# CH32X315 register map
Vendor: WCH Ltd.; File version: 1.1
Registers are 32-bit, read-write, reset 0x0 unless marked. A register's access mark holds for its fields unless they carry their own. Offsets are from the block's base; [hi:lo] are bit positions.

## RCC — Reset and clock control
Base 0x40021000
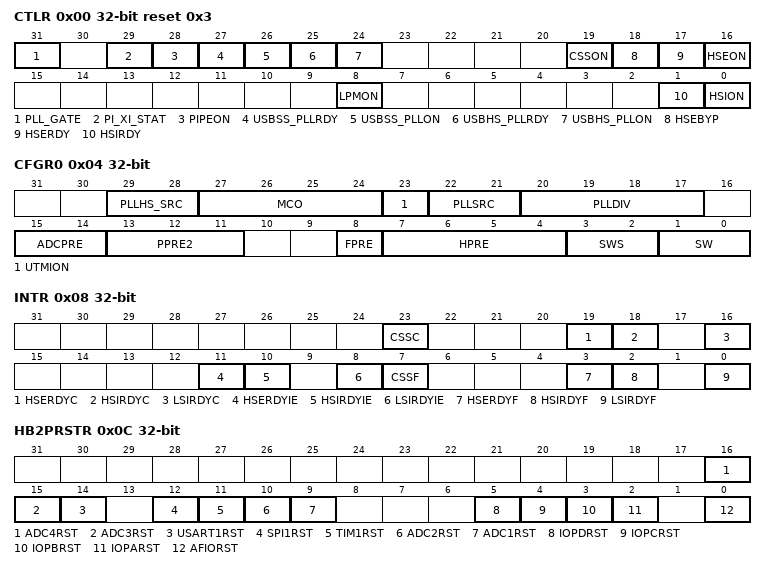
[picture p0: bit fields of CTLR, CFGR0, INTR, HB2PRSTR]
0x00 CTLR access per field reset 0x3 — Clock control register
  [31] PLL_GATE rw — PLL clock gating enablement
  [29] PI_XI_STAT ro — Crystal oscillator indication bit
  [28] PIPEON rw — PIPE clock gating enablement
  [27] USBSS_PLLRDY ro — USBSS PLL clock ready flag
  [26] USBSS_PLLON rw — USBSS PLL clock enable
  [25] USBHS_PLLRDY ro — USBHS PLL clock ready flag
  [24] USBHS_PLLON rw — USBHS PLL clock enable
  [19] CSSON rw — Clock Security System enable
  [18] HSEBYP rw — External High Speed clock Bypass
  [17] HSERDY ro — External High Speed clock ready flag
  [16] HSEON rw — External High Speed clock enable
  [8] LPMON rw — LMP clock enable
  [1] HSIRDY ro — Internal High Speed clock ready flag
  [0] HSION rw — Internal High Speed clock enable
0x04 CFGR0 access per field — Clock configuration register (RCC_CFGR0)
  [29:28] PLLHS_SRC rw — PLL clock selection
  [27:24] MCO rw — Microcontroller clock output
  [23] UTMION rw — UTMI clock gating enable
  [22:21] PLLSRC rw — PLLCLK clock selection
  [20:17] PLLDIV rw — The frequency division ratios of the UBSSS PLL 625M clock and USBHS PLL 480M clock
  [15:14] ADCPRE rw — ADC prescaler
  [13:11] PPRE2 rw — ADC clock prescaler (PB2)
  [8] FPRE rw — HCLK clock pre-divider selection
  [7:4] HPRE rw — HB prescaler
  [3:2] SWS ro — System Clock Switch Status
  [1:0] SW rw — System clock Switch
0x08 INTR access per field — Clock interrupt register (RCC_INTR)
  [23] CSSC wo — Clock security system interrupt clear
  [19] HSERDYC wo — HSE Ready Interrupt Clear
  [18] HSIRDYC wo — HSI Ready Interrupt Clear
  [16] LSIRDYC wo — LSI Ready Interrupt Clear
  [11] HSERDYIE rw — HSE Ready Interrupt Enable
  [10] HSIRDYIE rw — HSI Ready Interrupt Enable
  [8] LSIRDYIE rw — LSI Ready Interrupt Enable
  [7] CSSF ro — Clock Security System Interrupt flag
  [3] HSERDYF ro — HSE Ready Interrupt flag
  [2] HSIRDYF ro — HSI Ready Interrupt flag
  [0] LSIRDYF ro — LSI Ready Interrupt flag
0x0C HB2PRSTR — HB2 peripheral reset register (RCC_HB2PRSTR)
  [16] ADC4RST — ADC4 reset
  [15] ADC3RST — ADC3 reset
  [14] USART1RST — USART1 reset
  [12] SPI1RST — SPI 1 reset
  [11] TIM1RST — TIM1 timer reset
  [10] ADC2RST — ADC 2 interface reset
  [9] ADC1RST — ADC 1 interface reset
  [5] IOPDRST — IO port D reset
  [4] IOPCRST — IO port C reset
  [3] IOPBRST — IO port B reset
  [2] IOPARST — IO port A reset
  [0] AFIORST — Alternate function I/O reset
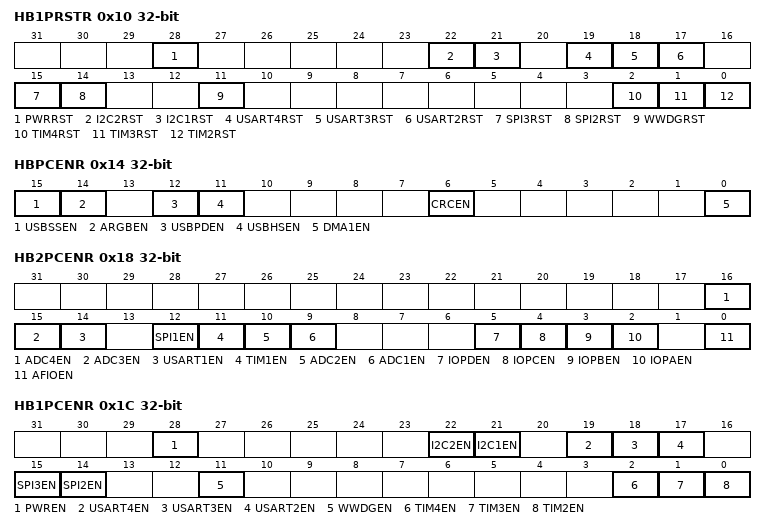
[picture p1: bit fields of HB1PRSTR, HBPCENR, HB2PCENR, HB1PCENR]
0x10 HB1PRSTR — HB1 peripheral reset register (RCC_HB1PRSTR)
  [28] PWRRST — Power interface reset
  [22] I2C2RST — I2C2 reset
  [21] I2C1RST — I2C1 reset
  [19] USART4RST — USART 4 reset
  [18] USART3RST — USART 3 reset
  [17] USART2RST — USART 2 reset
  [15] SPI3RST — SPI3 reset
  [14] SPI2RST — SPI2 reset
  [11] WWDGRST — Window watchdog reset
  [2] TIM4RST — Timer 4 reset
  [1] TIM3RST — Timer 3 reset
  [0] TIM2RST — Timer 2 reset
0x14 HBPCENR — HB Peripheral Clock enable register (RCC_HBPCENR)
  [15] USBSSEN — USBSS clock enable
  [14] ARGBEN — ARGB clock enable
  [12] USBPDEN — USBPD clock enable
  [11] USBHSEN — USBHS clock enable
  [6] CRCEN — CRC clock enable
  [0] DMA1EN — DMA clock enable
0x18 HB2PCENR — HB2 peripheral clock enable register (RCC_HB2PCENR)
  [16] ADC4EN — ADC4 clock enable
  [15] ADC3EN — ADC3 clock enable
  [14] USART1EN — USART1 clock enable
  [12] SPI1EN — SPI 1 clock enable
  [11] TIM1EN — TIM1 Timer clock enable
  [10] ADC2EN — ADC 2 interface clock enable
  [9] ADC1EN — ADC1 interface clock enable
  [5] IOPDEN — I/O port D clock enable
  [4] IOPCEN — I/O port C clock enable
  [3] IOPBEN — I/O port B clock enable
  [2] IOPAEN — I/O port A clock enable
  [0] AFIOEN — Alternate function I/O clock enable
0x1C HB1PCENR — HB1 peripheral clock enable register (RCC_HB1PCENR)
  [28] PWREN — Power interface clock enable
  [22] I2C2EN — I2C2 clock enable
  [21] I2C1EN — I2C1 clock enable
  [19] USART4EN — USART4 clock enable
  [18] USART3EN — USART3 clock enable
  [17] USART2EN — USART2 clock enable
  [15] SPI3EN — SPI3 clock enable
  [14] SPI2EN — SPI2 clock enable
  [11] WWDGEN — Window watchdog clock enable
  [2] TIM4EN — Timer 4 clock enable
  [1] TIM3EN — Timer 3 clock enable
  [0] TIM2EN — Timer 2 clock enable
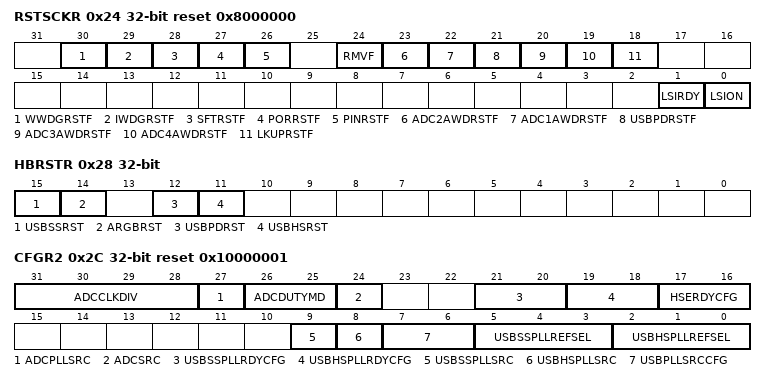
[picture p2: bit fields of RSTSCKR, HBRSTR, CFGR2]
0x24 RSTSCKR access per field reset 0x8000000 — Control/status register (RCC_RSTSCKR)
  [30] WWDGRSTF ro — Window watchdog reset flag
  [29] IWDGRSTF ro — Independent watchdog reset flag
  [28] SFTRSTF ro — Software reset flag
  [27] PORRSTF ro — POR/PDR reset flag
  [26] PINRSTF ro — PIN reset flag
  [24] RMVF rw — Remove reset flag
  [23] ADC2AWDRSTF ro — ADC2 watchdog reset flag
  [22] ADC1AWDRSTF ro — ADC1 watchdog flag
  [21] USBPDRSTF ro — USBPD reset flag
  [20] ADC3AWDRSTF ro — ADC3 watchdog reset flag
  [19] ADC4AWDRSTF ro — ADC4 watchdog flag
  [18] LKUPRSTF ro — LOCKUP reset flag
  [1] LSIRDY ro — Internal low speed oscillator ready
  [0] LSION rw — Internal low speed oscillator enable
0x28 HBRSTR — HB reset register (RCC_PHBRSTR)
  [15] USBSSRST — USBSS reset
  [14] ARGBRST — ARGB reset
  [12] USBPDRST — USBPD reset
  [11] USBHSRST — USBHS reset
0x2C CFGR2 reset 0x10000001 — Clock configuration register2 (RCC_CFGR2)
  [31:28] ADCCLKDIV — ADC input clock source selection uses the pre-divider control bits of either USBHS_PLL at 480MHz or USBSS_PLL at 625MHz
  [27] ADCPLLSRC — ADC input clock source selection
  [26:25] ADCDUTYMD — ADC clock duty cycle mode selection
  [24] ADCSRC — ADC input clock selection
  [21:20] USBSSPLLRDYCFG — USBSS PLL clock stable time configuration bit
  [19:18] USBHSPLLRDYCFG — USBHS PLL clock stable time configuration bit
  [17:16] HSERDYCFG — HSE clock stable time configuration bit
  [9] USBSSPLLSRC — USBSS PLL clock source selection
  [8] USBHSPLLSRC — USBHS PLL clock source selection
  [7:6] USBPLLSRCCFG — USB PLL clock source selection
  [5:3] USBSSPLLREFSEL — USBSS PLL refrence clock selection
  [2:0] USBHSPLLREFSEL — USBHS PLL refrence clock selection
